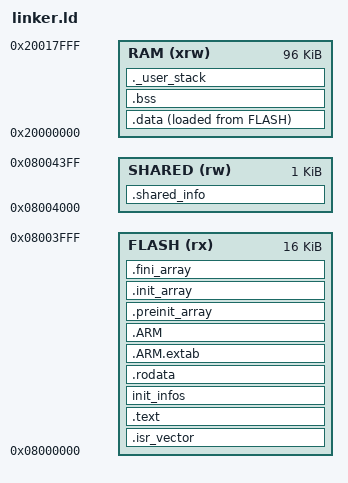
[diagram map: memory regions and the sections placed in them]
/* BLM Bootloader Linker Script - AT32F407VGT7 */
/* Bootloader: 8KB at 0x08000000 */
/* Shared: 1KB at 0x08002000 */

MEMORY
{
    FLASH (rx)      : ORIGIN = 0x08000000, LENGTH = 16K
    SHARED (rw)     : ORIGIN = 0x08004000, LENGTH = 1K
    RAM (xrw)       : ORIGIN = 0x20000000, LENGTH = 96K
}

ENTRY(Reset_Handler)

_Min_Stack_Size = 0x400;

SECTIONS
{
    .isr_vector :
    {
        . = ALIGN(4);
        KEEP(*(.isr_vector))
        . = ALIGN(4);
    } >FLASH

    .text :
    {
        . = ALIGN(4);
        *(.text)
        *(.text*)
        *(.glue_7)
        *(.glue_7t)
        *(.eh_frame)

        KEEP(*(.init))
        KEEP(*(.fini))

        . = ALIGN(4);
        _etext = .;
    } >FLASH

    init_infos :
    {
        . = ALIGN(4);
        __start_init_infos = .;
        KEEP(*(init_infos))
        __stop_init_infos = .;
        . = ALIGN(4);
    } >FLASH

    .rodata :
    {
        . = ALIGN(4);
        *(.rodata)
        *(.rodata*)
        . = ALIGN(4);
    } >FLASH

    .ARM.extab :
    {
        *(.ARM.extab* .gnu.linkonce.armextab.*)
    } >FLASH

    .ARM :
    {
        __exidx_start = .;
        *(.ARM.exidx*)
        __exidx_end = .;
    } >FLASH

    .preinit_array     :
    {
        PROVIDE_HIDDEN (__preinit_array_start = .);
        KEEP (*(.preinit_array*))
        PROVIDE_HIDDEN (__preinit_array_end = .);
    } >FLASH

    .init_array :
    {
        PROVIDE_HIDDEN (__init_array_start = .);
        KEEP (*(SORT(.init_array.*)))
        KEEP (*(.init_array*))
        PROVIDE_HIDDEN (__init_array_end = .);
    } >FLASH

    .fini_array :
    {
        PROVIDE_HIDDEN (__fini_array_start = .);
        KEEP (*(SORT(.fini_array.*)))
        KEEP (*(.fini_array*))
        PROVIDE_HIDDEN (__fini_array_end = .);
    } >FLASH

    .shared_info (NOLOAD) :
    {
        . = ALIGN(4);
        *(.shared_info)
        . = ALIGN(4);
    } >SHARED

    _sidata = LOADADDR(.data);
    .data :
    {
        . = ALIGN(4);
        _sdata = .;
        *(.data)
        *(.data*)
        . = ALIGN(4);
        _edata = .;
    } >RAM AT> FLASH

    .bss (NOLOAD) :
    {
        . = ALIGN(4);
        _sbss = .;
        __bss_start__ = _sbss;
        *(.bss)
        *(.bss*)
        *(COMMON)
        . = ALIGN(4);
        _ebss = .;
        __bss_end__ = _ebss;
    } >RAM

    ._user_stack (NOLOAD) :
    {
        . = ALIGN(8);
        . = . + _Min_Stack_Size;
        . = ALIGN(8);
        _estack = .;
    } >RAM

    /DISCARD/ :
    {
        libc.a ( * )
        libm.a ( * )
        libgcc.a ( * )
    }

    .ARM.attributes 0 : { *(.ARM.attributes) }
}
